# HK32F030M register map
Vendor: HKMicroChip Ltd.; Series: HK32F030M; File version: 1.0
CPU: CM0 r0p0, little endian, no MPU, no FPU, 3 interrupt priority bits
Registers are 32-bit, read-write, reset 0x0 unless marked. A register's access mark holds for its fields unless they carry their own. Offsets are from the block's base; [hi:lo] are bit positions.

## IOMUX
Base 0x40017C00
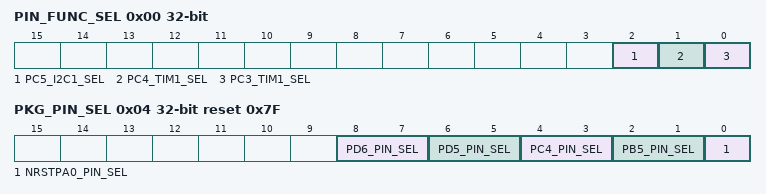
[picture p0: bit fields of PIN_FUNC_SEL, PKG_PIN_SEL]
0x00 PIN_FUNC_SEL — PIN function select register
  [2] PC5_I2C1_SEL — I2C1 pin select
  [1] PC4_TIM1_SEL — timer1 pin select
  [0] PC3_TIM1_SEL — timer1 pin select
0x04 PKG_PIN_SEL reset 0x7F
  [8:7] PD6_PIN_SEL
  [6:5] PD5_PIN_SEL
  [4:3] PC4_PIN_SEL
  [2:1] PB5_PIN_SEL
  [0] NRSTPA0_PIN_SEL — NRST PA0 function select
0x08 NRST_PIN_KEY
  [14:0] NRST_PIN_KEY
0x0C NRST_PA0_SEL
  [0] NRST_PA0_SEL
0x10 TIM2_CH0_IN_SEL
  [1:0] TIM2_CH0_IN_SEL

## SPI — Serial peripheral interface
Base 0x40013000
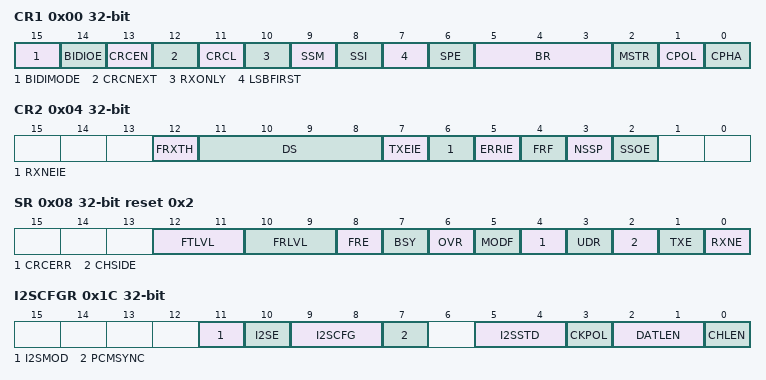
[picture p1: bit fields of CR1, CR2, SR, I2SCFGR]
0x00 CR1 — control register 1
  [15] BIDIMODE — Bidirectional data mode enable
  [14] BIDIOE — Output enable in bidirectional mode
  [13] CRCEN — Hardware CRC calculation enable
  [12] CRCNEXT — CRC transfer next
  [11] CRCL — CRC lenth
  [10] RXONLY — Receive only
  [9] SSM — Software slave management
  [8] SSI — Internal slave select
  [7] LSBFIRST — Frame format
  [6] SPE — SPI enable
  [5:3] BR — Baud rate control
  [2] MSTR — Master selection
  [1] CPOL — Clock polarity
  [0] CPHA — Clock phase
0x04 CR2 — control register 2
  [12] FRXTH — FIFO reception threshold
  [11:8] DS — Data size
  [7] TXEIE — Tx buffer empty interrupt enable
  [6] RXNEIE — RX buffer not empty interrupt enable
  [5] ERRIE — Error interrupt enable
  [4] FRF — Frame format
  [3] NSSP — NSS pulse management
  [2] SSOE — SS output enable
0x08 SR access per field reset 0x2 — status register
  [12:11] FTLVL ro — FIFO transmission level
  [10:9] FRLVL ro — FIFO reception level
  [8] FRE ro — frame format error
  [7] BSY ro — Busy flag
  [6] OVR ro — Overrun flag
  [5] MODF ro — Mode fault
  [4] CRCERR rw — CRC error flag
  [3] UDR ro — Underrun flag
  [2] CHSIDE ro — Channel side
  [1] TXE ro — Transmit buffer empty
  [0] RXNE ro — Receive buffer not empty
0x0C DR — data register
  [15:0] DR — Data register
0x10 CRCPR reset 0x7 — CRC polynomial register
  [15:0] CRCPOLY
0x14 RXCRCR ro — RX CRC register
  [15:0] RxCRC
0x18 TXCRCR ro — TX CRC register
  [15:0] TxCRC
0x1C I2SCFGR — I2S configuration register
  [11] I2SMOD — I2S mode selection
  [10] I2SE — I2S Enable
  [9:8] I2SCFG — I2S configuration mode
  [7] PCMSYNC — PCM frame synchronization
  [5:4] I2SSTD — I2S standard selection
  [3] CKPOL — Steady state clock polarity
  [2:1] DATLEN — Data length to be transferred
  [0] CHLEN — Channel length (number of bits per audio channel)
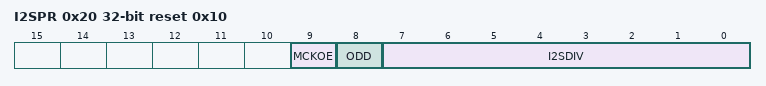
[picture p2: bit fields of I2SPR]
0x20 I2SPR reset 0x10 — I2S prescaler register
  [9] MCKOE — Master clock output enable
  [8] ODD — Odd factor for the prescaler
  [7:0] I2SDIV — I2S Linear prescaler

## PWR — Power control
Base 0x40007000
0x00 CR — power control register
  [0] LPDS — Low-power deep sleep

## IWDG — Independent watchdog
Base 0x40003000
0x00 KR wo — Key register
  [15:0] KEY — Key value
0x04 PR — Prescaler register
  [2:0] PR — Prescaler divider
0x08 RLR reset 0xFFF — Reload register
  [11:0] RL — Watchdog counter reload value
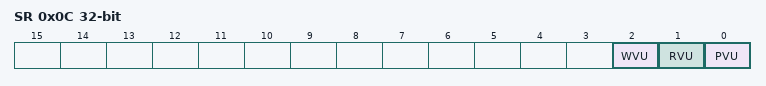
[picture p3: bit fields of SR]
0x0C SR ro — Status register
  [2] WVU — Watchdog counter window value update
  [1] RVU — Watchdog counter reload value update
  [0] PVU — Watchdog prescaler value update
0x10 WINR reset 0xFFF — Window register
  [11:0] WIN — Watchdog counter window value

## WWDG — Window watchdog
Base 0x40002C00
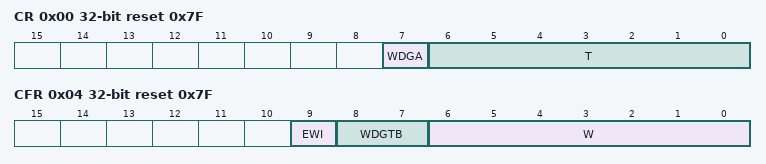
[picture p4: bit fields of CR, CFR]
0x00 CR reset 0x7F — Control register
  [7] WDGA — Activation bit
  [6:0] T — 7-bit counter
0x04 CFR reset 0x7F — Configuration register
  [9] EWI — Early wakeup interrupt
  [8:7] WDGTB — Timer base
  [6:0] W — 7-bit window value
0x08 SR — Status register
  [0] EWIF — Early wakeup interrupt flag

## TIM6 — Basic-timers
Base 0x40001000
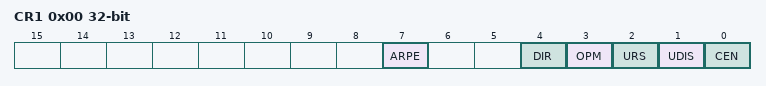
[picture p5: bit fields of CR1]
0x00 CR1 — control register 1
  [7] ARPE — Auto-reload preload enable
  [4] DIR — Direction
  [3] OPM — One-pulse mode
  [2] URS — Update request source
  [1] UDIS — Update disable
  [0] CEN — Counter enable
0x04 CR2 — control register 2
  [6:4] MMS — Master mode selection
0x0C DIER — Interrupt enable register
  [0] UIE — Update interrupt enable
0x10 SR — status register
  [0] UIF — Update interrupt flag
0x14 EGR wo — event generation register
  [0] UG — Update generation
0x24 CNT — counter
  [15:0] CNT — Low counter value
0x28 PSC — prescaler
  [15:0] PSC — Prescaler value
0x2C ARR — auto-reload register
  [15:0] ARR — Low Auto-reload value
